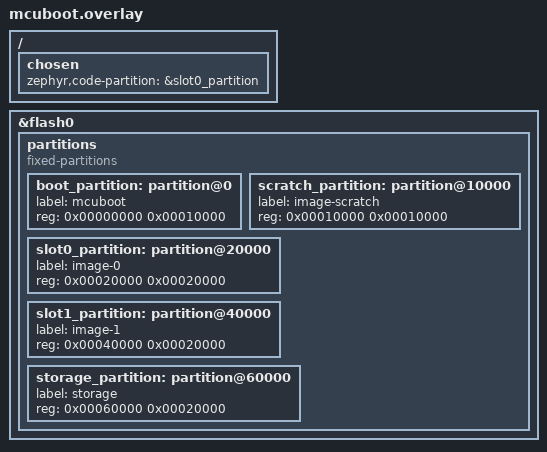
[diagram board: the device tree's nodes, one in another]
/ {
	chosen {
		zephyr,code-partition = &slot0_partition;
	};
};

&flash0 {
	/delete-node/ partitions;

	partitions {
		compatible = "fixed-partitions";
		#address-cells = <1>;
		#size-cells = <1>;

		boot_partition: partition@0 {
			label = "mcuboot";
			reg = <0x00000000 0x00010000>;
		};

		scratch_partition: partition@10000 {
			label = "image-scratch";
			reg = <0x00010000 0x00010000>;
		};

		slot0_partition: partition@20000 {
			label = "image-0";
			reg = <0x00020000 0x00020000>;
		};

		slot1_partition: partition@40000 {
			label = "image-1";
			reg = <0x00040000 0x00020000>;
		};

		storage_partition: partition@60000 {
			label = "storage";
			reg = <0x00060000 0x00020000>;
		};
	};
};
